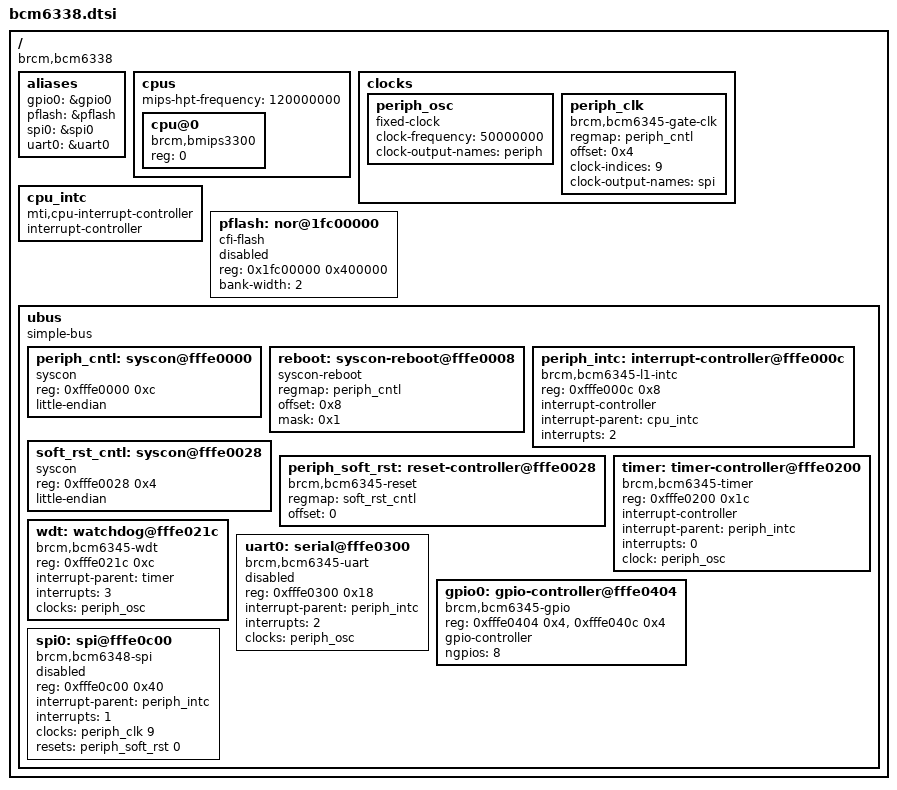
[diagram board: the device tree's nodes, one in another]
#include <dt-bindings/gpio/gpio.h>
#include <dt-bindings/input/input.h>

/ {
	#address-cells = <1>;
	#size-cells = <1>;
	compatible = "brcm,bcm6338";

	aliases {
		gpio0 = &gpio0;
		pflash = &pflash;
		spi0 = &spi0;
		uart0 = &uart0;
	};

	cpus {
		#address-cells = <1>;
		#size-cells = <0>;
		mips-hpt-frequency = <120000000>;

		cpu@0 {
			compatible = "brcm,bmips3300", "mips,mips4Kc";
			device_type = "cpu";
			reg = <0>;
		};
	};

	clocks {
		periph_osc: periph_osc {
			compatible = "fixed-clock";

			#clock-cells = <0>;

			clock-frequency = <50000000>;
			clock-output-names = "periph";
		};

		periph_clk: periph_clk {
			compatible = "brcm,bcm6345-gate-clk";
			regmap = <&periph_cntl>;
			offset = <0x4>;

			#clock-cells = <1>;

			clock-indices = <9>;
			clock-output-names = "spi";

			/*
			 0: adsl_phy
			 1: mpi
			 2: dram
			 4: enet/usbs
			 5: sar
			 9: spi
			*/
		};
	};

	cpu_intc: cpu_intc {
		#address-cells = <0>;
		compatible = "mti,cpu-interrupt-controller";

		interrupt-controller;
		#interrupt-cells = <1>;
	};

	pflash: nor@1fc00000 {
		#address-cells = <1>;
		#size-cells = <1>;
		compatible = "cfi-flash";
		reg = <0x1fc00000 0x400000>;
		bank-width = <2>;

		status = "disabled";
	};

	ubus {
		#address-cells = <1>;
		#size-cells = <1>;

		compatible = "simple-bus";
		ranges;

		periph_cntl: syscon@fffe0000 {
			compatible = "syscon";
			reg = <0xfffe0000 0xc>;
			little-endian;
		};

		reboot: syscon-reboot@fffe0008 {
			compatible = "syscon-reboot";
			regmap = <&periph_cntl>;
			offset = <0x8>;
			mask = <0x1>;
		};

		periph_intc: interrupt-controller@fffe000c {
			compatible = "brcm,bcm6345-l1-intc";
			reg = <0xfffe000c 0x8>;

			interrupt-controller;
			#interrupt-cells = <1>;

			interrupt-parent = <&cpu_intc>;
			interrupts = <2>;
		};

		soft_rst_cntl: syscon@fffe0028 {
			compatible = "syscon";
			reg = <0xfffe0028 0x4>;
			little-endian;
		};

		periph_soft_rst: reset-controller@fffe0028 {
			compatible = "brcm,bcm6345-reset";
			regmap = <&soft_rst_cntl>;
			offset = <0>;

			#reset-cells = <1>;

			/*
			 0: spi
			 2: enet
			 3: usbh
			 4: usbs
			 5: adsl
			 6: dmamem
			 7: sar
			 8: aclc
			 10: adsl_mips_pll
			*/
		};

		timer: timer-controller@fffe0200 {
			compatible = "brcm,bcm6345-timer";
			reg = <0xfffe0200 0x1c>;

			interrupt-controller;
			#interrupt-cells = <1>;

			interrupt-parent = <&periph_intc>;
			interrupts = <0>;

			clock = <&periph_osc>;
		};

		wdt: watchdog@fffe021c {
			compatible = "brcm,bcm6345-wdt";
			reg = <0xfffe021c 0xc>;

			interrupt-parent = <&timer>;
			interrupts = <3>;

			clocks = <&periph_osc>;
		};

		uart0: serial@fffe0300 {
			compatible = "brcm,bcm6345-uart";
			reg = <0xfffe0300 0x18>;

			interrupt-parent = <&periph_intc>;
			interrupts = <2>;

			clocks = <&periph_osc>;

			status = "disabled";
		};

		gpio0: gpio-controller@fffe0404 {
			compatible = "brcm,bcm6345-gpio";
			reg = <0xfffe0404 0x4>, <0xfffe040c 0x4>;

			gpio-controller;
			#gpio-cells = <2>;

			ngpios = <8>;
		};

		spi0: spi@fffe0c00 {
			compatible = "brcm,bcm6348-spi";
			reg = <0xfffe0c00 0x40>;
			#address-cells = <1>;
			#size-cells = <1>;

			interrupt-parent = <&periph_intc>;
			interrupts = <1>;

			clocks = <&periph_clk 9>;
			clock-names = "spi";

			resets = <&periph_soft_rst 0>;

			status = "disabled";
		};
	};
};
